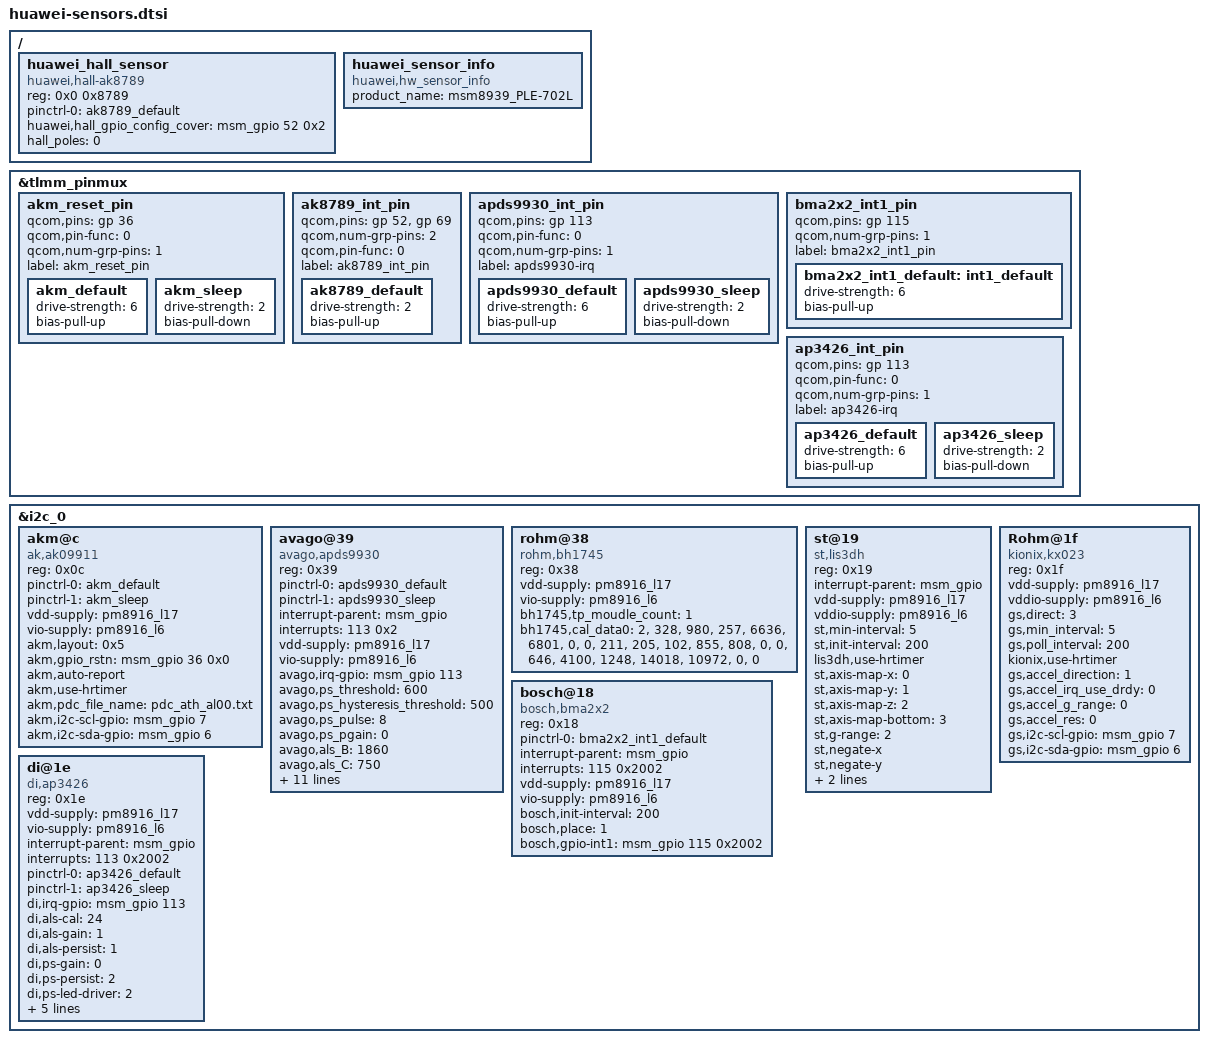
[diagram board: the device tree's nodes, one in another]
/* < DTS2015071605523 guotiecheng 20150716 begin */
/*use fromdos convert file format to linux*/
/* Copyright (c) 2013 The Linux Foundation. All rights reserved.
 *
 * This program is free software; you can redistribute it and/or modify
 * it under the terms of the GNU General Public License version 2 and
 * only version 2 as published by the Free Software Foundation.
 *
 * This program is distributed in the hope that it will be useful,
 * but WITHOUT ANY WARRANTY; without even the implied warranty of
 * MERCHANTABILITY or FITNESS FOR A PARTICULAR PURPOSE.  See the
 * GNU General Public License for more details.
 */
&tlmm_pinmux {
	akm_reset_pin {
		qcom,pins = <&gp 36>;
		qcom,pin-func = <0>;
		qcom,num-grp-pins = <1>;
		label = "akm_reset_pin";
		akm_default: akm_default {
			drive-strength = <6>;
			bias-pull-up;
		};
		akm_sleep: akm_sleep {
			drive-strength = <2>;
			bias-pull-down;
		};
	};

/* DTS2015012910874 dingjingfeng 20150206 begin> */
//delete lines
/* DTS2015012910874 dingjingfeng 20150206 end> */
	ak8789_int_pin {
		qcom,pins = <&gp 52>, <&gp 69>;
		qcom,num-grp-pins = <2>;
		qcom,pin-func = <0>;
		label = "ak8789_int_pin";
		ak8789_default: ak8789_default {
			  drive-strength = <2>;
			  bias-pull-up;
		};
	};
	apds9930_int_pin {
		qcom,pins = <&gp 113>;
		qcom,pin-func = <0>;
		qcom,num-grp-pins = <1>;
		label = "apds9930-irq";
		apds9930_default: apds9930_default {
			drive-strength = <6>;
			bias-pull-up;
		};
		apds9930_sleep: apds9930_sleep {
			drive-strength = <2>;
			bias-pull-down;
		};
	};
	/*<DTS2015072101855 chendong cwx241705 begin  */
	//delete
	/*DTS2015072101855 chendong cwx241705 end>  */
/* < DTS2015011203894 Zhangbo 00166742 20150112 begin */
/* delete some lines */
/* DTS2015011203894 Zhangbo 00166742 20150112 end > */
/* < DTS2015112600367  chendong 20151126 begin */
	bma2x2_int1_pin {
		qcom,pins = <&gp 115>;
		qcom,num-grp-pins = <1>;
		label = "bma2x2_int1_pin";
		bma2x2_int1_default: int1_default {
			drive-strength = <6>;
			bias-pull-up;
		};
	};
	ap3426_int_pin {
		qcom,pins = <&gp 113>;
		qcom,pin-func = <0>;
		qcom,num-grp-pins = <1>;
		label = "ap3426-irq";
		ap3426_default: ap3426_default {
			drive-strength = <6>;
			bias-pull-up;
		};
		ap3426_sleep: ap3426_sleep {
			drive-strength = <2>;
			bias-pull-down;
		};
	};
/* DTS2015112600367  chendong 20151126 end > */
};

&i2c_0 { /* BLSP1 QUP2 */
	akm@c {
		compatible = "ak,ak09911";
		reg = <0x0c>;
		pinctrl-names = "default","sleep";
		pinctrl-0 = <&akm_default>;
		pinctrl-1 = <&akm_sleep>;
		vdd-supply = <&pm8916_l17>;
		vio-supply = <&pm8916_l6>;
		/* < DTS2015120303965  chendong 20151126 begin */
		akm,layout = <0x5>;
		/* DTS2015120303965  chendong 20151126 end > */
		akm,gpio_rstn = <&msm_gpio 36 0x0>;
		akm,auto-report;
		/* < DTS2015052009130 hufeng 20150601 begin */
		akm,use-hrtimer;
		/*  DTS2015052009130 hufeng 20150601 end > */
		/* < DTS2015032800844 caowei 20150319 begin */
		akm,pdc_file_name = "pdc_ath_al00.txt";
		akm,i2c-scl-gpio = <&msm_gpio 7 0x0>;
		akm,i2c-sda-gpio = <&msm_gpio 6 0x0>;
		/* DTS2015032800844 caowei 20150319 end > */
	};

	avago@39 {
		compatible = "avago,apds9930";
		reg = <0x39>;
		pinctrl-names = "default","sleep";
		pinctrl-0 = <&apds9930_default>;
		pinctrl-1 = <&apds9930_sleep>;
		interrupt-parent = <&msm_gpio>;
		interrupts = <113 0x2>;
		vdd-supply = <&pm8916_l17>;
		vio-supply = <&pm8916_l6>;
		avago,irq-gpio = <&msm_gpio 113 0x2>;
		avago,ps_threshold = <600>;
		avago,ps_hysteresis_threshold = <500>;
		avago,ps_pulse = <8>;
		avago,ps_pgain = <0>;
		avago,als_B = <1860>;
		avago,als_C = <750>;
		avago,als_D = <1290>;
		avago,ga_value = <48>;
	        avago,ga_a_value = <112>;
		avago,ga_c_value = <450>;
		avago,ga_d_value = <162>;
		avago,window = <110>;
		avago,wave = <84>;
		avago,ga_e_value = <220>;
		avago,ga_f_value = <43>;
		/* < DTS2015032800844 caowei 20150319 begin */
		avago,i2c-scl-gpio = <&msm_gpio 7 0x0>;
		avago,i2c-sda-gpio = <&msm_gpio 6 0x0>;
		/* DTS2015032800844 caowei 20150319 end > */
	};
	/*<DTS2015072101855 chendong cwx241705 begin  */
	rohm@38 {
        compatible = "rohm,bh1745";
        reg = <0x38>;
        vdd-supply = <&pm8916_l17>;
        vio-supply = <&pm8916_l6>;
        /* < DTS2015040700192 wushengyu 20150407 begin */
        /* < DTS2015032301235 chenyang 20150423 begin */
        bh1745,tp_moudle_count = <1>;
        /*[module_id] [golden judge] r[0] r[1] g[0] g[1] b[0] b[1]*/
        bh1745,cal_data0 = "2","328","980","257","6636","6801","0","0",
        /*[white judge] r[0] r[1] g[0]  g[1] b[0] b[1]*/
        "211","205","102","855","808","0","0",
        /*[blue judge] r[0] r[1] g[0] g[1] b[0] b[1]*/
        "646","4100","1248","14018","10972","0","0";
        /* DTS2015032301235 chenyang 20150423 end > */
        /* DTS2015040700192 wushengyu 20150407 end > */
    };
	st@19 {
		compatible = "st,lis3dh";
		reg = <0x19>;
/* DTS2015012910874 dingjingfeng 20150206 begin> */
//delete lines
/* DTS2015012910874 dingjingfeng 20150206 end> */
	/*DTS2015072101855 chendong cwx241705 end>  */
		interrupt-parent = <&msm_gpio>;
		vdd-supply = <&pm8916_l17>;
		vddio-supply = <&pm8916_l6>;
		st,min-interval = <5>;
		st,init-interval = <200>;
		/*  DTS2015052009130 hufeng 20150601 end > */
		lis3dh,use-hrtimer;
		/* < DTS2015052009130 hufeng 20150601 begin */
		st,axis-map-x = <0>;
		st,axis-map-y = <1>;
		st,axis-map-z = <2>;
		/*1 is bottom and others means top*/
		/* <DTS2015072101855 chendong 20150812 begin */
		st,axis-map-bottom=<3>;
		/* DTS2015072101855 chendong 20150812 end> */
		st,g-range = <2>;
/* DTS2015012910874 dingjingfeng 20150206 begin> */
//delete lines
/* DTS2015012910874 dingjingfeng 20150206 end> */
		st,negate-x;
		st,negate-y;
		/* < DTS2015032800844 caowei 20150319 begin */
		st,i2c-scl-gpio = <&msm_gpio 7 0x0>;
		st,i2c-sda-gpio = <&msm_gpio 6 0x0>;
		/* DTS2015032800844 caowei 20150319 end > */
	};
	/*<DTS2015072101855 chendong cwx241705 begin  */
	Rohm@1f {
		compatible = "kionix,kx023";
		reg = <0x1f>;
/* DTS2015012910874 dingjingfeng 20150206 begin> */
//delete lines
/* DTS2015012910874 dingjingfeng 20150206 end> */
	/*DTS2015072101855 chendong cwx241705 end>  */
		vdd-supply = <&pm8916_l17>;
		vddio-supply = <&pm8916_l6>;
		/* < DTS2014042813729 yangzhonghua 20140428 begin */
/* DTS2015012910874 dingjingfeng 20150206 begin> */
//delete lines
/* DTS2015012910874 dingjingfeng 20150206 end> */
		/* DTS2014042813729  yangzhonghua 20140428 end > */
		/* < DTS2014102905500 chuguoliang 20141029 begin */
		/*1 is bottom and others means top*/
		/* <DTS2015072101855 chendong 20150812 begin */
		gs,direct = <3>;
		/* DTS2015072101855 chendong 20150812 end> */
		/* DTS2014102905500 chuguoliang 20141029 end > */
		gs,min_interval = <5>;
		gs,poll_interval = <200>;
		/* < DTS2015052009130 hufeng 20150601 begin */
		kionix,use-hrtimer;
		/*  DTS2015052009130 hufeng 20150601 end > */
		gs,accel_direction = <1>;
		gs,accel_irq_use_drdy = <0>;
		gs,accel_g_range = <0>;
		gs,accel_res = <0>;
		/* < DTS2015032800844 caowei 20150319 begin */
		gs,i2c-scl-gpio = <&msm_gpio 7 0x0>;
		gs,i2c-sda-gpio = <&msm_gpio 6 0x0>;
		/* DTS2015032800844 caowei 20150319 end > */
	};
	
/* < DTS2015011203894 Zhangbo 00166742 20150112 begin */
/* delete some lines */
/* DTS2015011203894 Zhangbo 00166742 20150112 end > */
/* < DTS2015112600367  chendong 20151126 begin */
/* < DTS2016040502547  chendong 20160407 begin */
	bosch@18 { /* Accelerometer sensor */
		compatible = "bosch,bma2x2";
		reg = <0x18>;
		pinctrl-names = "default";
		pinctrl-0 = <&bma2x2_int1_default>;
		interrupt-parent = <&msm_gpio>;
		interrupts = <115 0x2002>;
		vdd-supply = <&pm8916_l17>;
		vio-supply = <&pm8916_l6>;
		bosch,init-interval = <200>;
		/* < DTS2015120303965  chendong 20151126 begin */
		bosch,place = <1>;
		/* DTS2015120303965  chendong 20151126 end > */
		bosch,gpio-int1 = <&msm_gpio 115 0x2002>;
	};
	di@1e {
		compatible = "di,ap3426";
		reg = <0x1e>;
		vdd-supply = <&pm8916_l17>;
		vio-supply = <&pm8916_l6>;
		interrupt-parent = <&msm_gpio>;
		interrupts = <113 0x2002>;
		pinctrl-names = "default","sleep";
		pinctrl-0 = <&ap3426_default>;
		pinctrl-1 = <&ap3426_sleep>;
		di,irq-gpio = <&msm_gpio 113 0x2002>;
		di,als-cal = <24>;
		di,als-gain = <1>;
		di,als-persist = <1>;
		di,ps-gain = <0>;
		di,ps-persist = <2>;
		di,ps-led-driver = <2>;
		di,ps-mean-time = <1>;
		di,ps-integrated-time = <7>;
		di,ps-distance-table = <100 50>;
		di,als-sensitivity = <200 40 10 1>;
		di,wakeup-threshold = <1>;
	};
/* DTS2016040502547  chendong 20160407 end > */
/* DTS2015112600367  chendong 20151126 end > */
};
/{
	huawei_hall_sensor{
		compatible = "huawei,hall-ak8789";
		reg = <0x0 0x8789>;
		pinctrl-names = "default";
		pinctrl-0 = <&ak8789_default>;
		/* < DTS2015120303965  chendong 20151126 begin */	
		huawei,hall_gpio_config_cover = <&msm_gpio 52 0x2>;
		hall_poles = <0>;
		/* DTS2015120303965  chendong 20151126 end > */
		status = "ok";
	};
};
/* DTS2014121804508 wangcunyou 20141218 end > */
/*<DTS2015072101855 chendong cwx241705 begin  */
/* < DTS2015020511013 wangcunyou 20150205 begin */
/{
	huawei_sensor_info {
		compatible = "huawei,hw_sensor_info";
		product_name = "msm8939_PLE-702L";
	};
};
/* DTS2015020511013 wangcunyou 20150205 end > */
/*DTS2015072101855 chendong cwx241705 end>  */
/* DTS2015071605523 guotiecheng 20150716 end >*/
